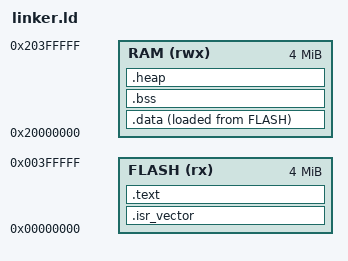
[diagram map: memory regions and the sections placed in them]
/* QEMU mps2-an385: 4 MiB flash at 0x00000000, 4 MiB RAM at 0x20000000. */
ENTRY(Reset_Handler)

_estack = ORIGIN(RAM) + LENGTH(RAM);

MEMORY
{
    FLASH (rx)  : ORIGIN = 0x00000000, LENGTH = 4M
    RAM   (rwx) : ORIGIN = 0x20000000, LENGTH = 4M
}

SECTIONS
{
    .isr_vector :
    {
        KEEP(*(.isr_vector))
        . = ALIGN(4);
    } > FLASH

    .text :
    {
        *(.text*)
        *(.rodata*)
        . = ALIGN(4);
        _etext = .;
    } > FLASH

    _sidata = LOADADDR(.data);

    .data : ALIGN(4)
    {
        _sdata = .;
        *(.data*)
        . = ALIGN(4);
        _edata = .;
    } > RAM AT > FLASH

    .bss (NOLOAD) : ALIGN(4)
    {
        _sbss = .;
        *(.bss*)
        *(COMMON)
        . = ALIGN(4);
        _ebss = .;
    } > RAM

    /* heap_3 wraps newlib malloc; give it a small heap in RAM. */
    .heap (NOLOAD) :
    {
        PROVIDE(end = .);
        . = . + 32K;
        gdr_heap_limit = .;
    } > RAM
}
